# GENERAL register map
Vendor: Texas Instruments
Peripheral module from a debugger description file (folder omap34xx).
Registers are 32-bit, read-only, reset 0x0 unless marked. A register's access mark holds for its fields unless they carry their own. Offsets are as the file gives them; lines under a group give offsets from that group; [hi:lo] are bit positions; {n}, {i} and the like mark numbered series; 'fields as' and 'values as' point back to an identical list; <NAME> marks a mode.

## GENERAL
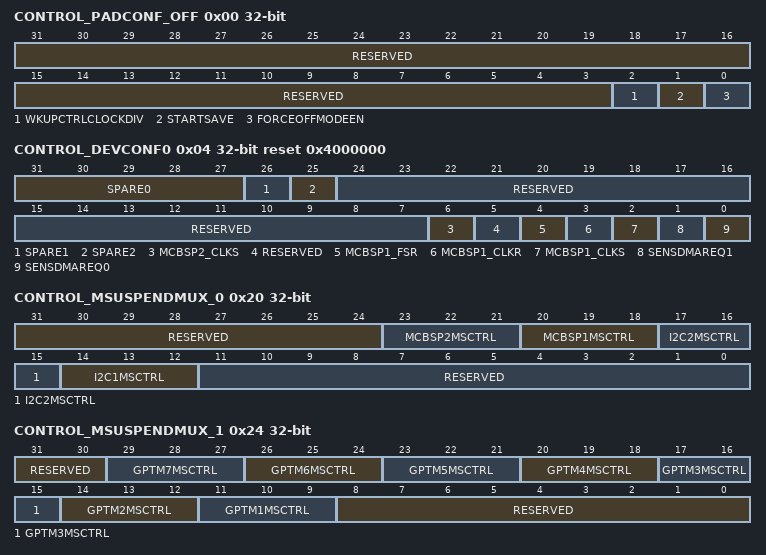
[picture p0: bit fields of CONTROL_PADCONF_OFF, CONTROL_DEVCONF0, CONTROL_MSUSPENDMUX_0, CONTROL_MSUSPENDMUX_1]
0x00 CONTROL_PADCONF_OFF access per field — Off mode pad configuration register
  [31:3] RESERVED ro — Read returns reset value.
  [2] WKUPCTRLCLOCKDIV rw — Wkup_ctrl module clock divider
  [1] STARTSAVE rw — Start pad configuration registers save mechanism
  [0] FORCEOFFMODEEN rw — Force OFF mode active
0x04 CONTROL_DEVCONF0 access per field reset 0x4000000 — Static device configuration register-0. Module dedicated functions
  [31:27] SPARE0 rw — Spare bits
  [26] SPARE1 rw — Spare bit
  [25] SPARE2 rw — Spare bit
  [24:7] RESERVED ro — Read returns reset value
  [6] MCBSP2_CLKS rw — Select the CLKS input for the module McBSP2Note : There are no external pins McBSP2_CLKR and McBSP2_FSR for the module McBSP2. For this module, CLKR input is from the pin McBSP2_CLKX and FSR input is from the pin McBSP2_FSX .
  [5] RESERVED ro — Read returns reset value.
  [4] MCBSP1_FSR rw — Select the FSR input for the module McBSP1
  [3] MCBSP1_CLKR rw — Select the CLKR input for the module McBSP1
  [2] MCBSP1_CLKS rw — Select the CLKS input for the module McBSP1
  [1] SENSDMAREQ1 rw — Set sensitivity on SYS.DMAREQ1 input pin
  [0] SENSDMAREQ0 rw — Set sensitivity on SYS.DMAREQ0 input pin
0x20 CONTROL_MSUSPENDMUX_0 access per field — MSuspend Control register: control the use of MSuspend signals at module level
  [31:24] RESERVED ro — Read returns reset value.
  [23:21] MCBSP2MSCTRL rw — Control McBSP_2 sensitivity to MCU and/or DSP MSuspend signals
  [20:18] MCBSP1MSCTRL rw — Control McBSP_1 sensitivity to MCU and/or DSP MSuspend signals
  [17:15] I2C2MSCTRL rw — Control I2C_2 sensitivity to MCU and/or DSP MSuspend signals
  [14:12] I2C1MSCTRL rw — Control I2C_1 sensitivity to MCU and/or DSP MSuspend signals
  [11:0] RESERVED ro — Read returns reset value.
0x24 CONTROL_MSUSPENDMUX_1 access per field — MSuspend Control register : control the use of MSuspend signals at module level
  [31:30] RESERVED ro — Read returns reset value.
  [3n+8:3n+6] GPTM{n}MSCTRL rw (n=1..7) — Control General Purpose Timer {n} sensitivity to MCU and/or DSP MSuspend signals
  [8:0] RESERVED ro — Read returns reset value.
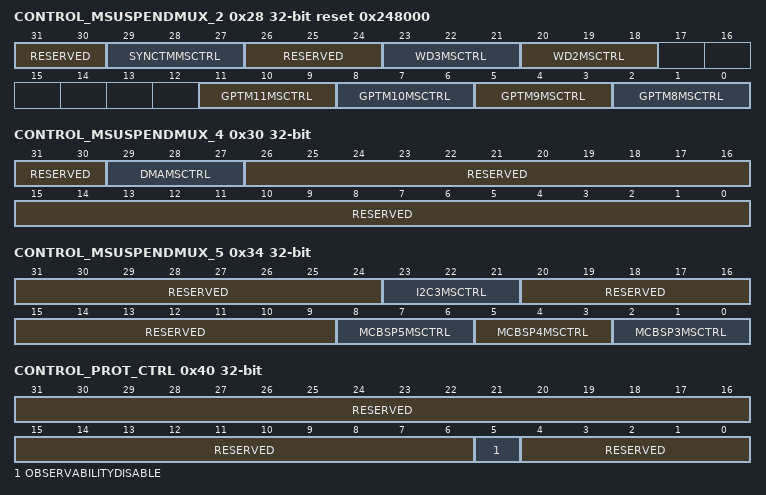
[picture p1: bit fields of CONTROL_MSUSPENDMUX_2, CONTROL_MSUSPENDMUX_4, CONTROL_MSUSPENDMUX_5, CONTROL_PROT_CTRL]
0x28 CONTROL_MSUSPENDMUX_2 access per field reset 0x248000 — MSuspend Control register : control the use of MSuspend signals at module level
  [31:30] RESERVED ro — Read returns reset value.
  [29:27] SYNCTMMSCTRL rw — Control Sync Timer32K sensitivity to MCU and/or DSP MSuspend signals
  [26:24] RESERVED ro — Read returns reset value.
  [23:21] WD3MSCTRL rw — Control Watch Dog 4 sensitivity to MCU and/or DSP MSuspend signals
  [20:18] WD2MSCTRL rw — Control Watch Dog 2 sensitivity to MCU and/or DSP MSuspend signals
  [3n-22:3n-24] GPTM{n}MSCTRL rw (n=8..11) — Control General Purpose Timer {n} sensitivity to MCU and/or DSP MSuspend signals
0x2C CONTROL_MSUSPENDMUX_3 — MSuspend Control register : control the use of MSuspend signals at module level
  [31:0] RESERVED — Read returns reset value.
0x30 CONTROL_MSUSPENDMUX_4 access per field — MSuspend Control register: control the use of MSuspend signals at module level
  [31:30] RESERVED ro — Read returns reset value.
  [29:27] DMAMSCTRL rw — Control DMA sensitivity to MCU and/or DSP MSuspend signals
  [26:0] RESERVED ro — Read returns reset value.
0x34 CONTROL_MSUSPENDMUX_5 access per field — MSuspend Control register: control the use of MSuspend signals at module levelNot used
  [31:24] RESERVED ro — Read returns reset value.
  [23:21] I2C3MSCTRL rw — Control I2C-3 Sensitivity to MCU and/or DSP MSuspend Signals
  [20:9] RESERVED ro — Read returns reset value.
  [8:6] MCBSP5MSCTRL rw — Control McBSP-5 Sensitivity to MCU and/or DSP MSuspend Signals
  [5:3] MCBSP4MSCTRL rw — Control McBSP-4 Sensitivity to MCU and/or DSP MSuspend Signals
  [2:0] MCBSP3MSCTRL rw — Control McBSP-3 Sensitivity to MCU and/or DSP MSuspend Signals
0x40 CONTROL_PROT_CTRL access not given — Control register
  [31:6] RESERVED ro — Read returns reset value
  [5] OBSERVABILITYDISABLE — Control the observability feature (access R/OCO)
  [4:0] RESERVED ro — Read returns reset value.
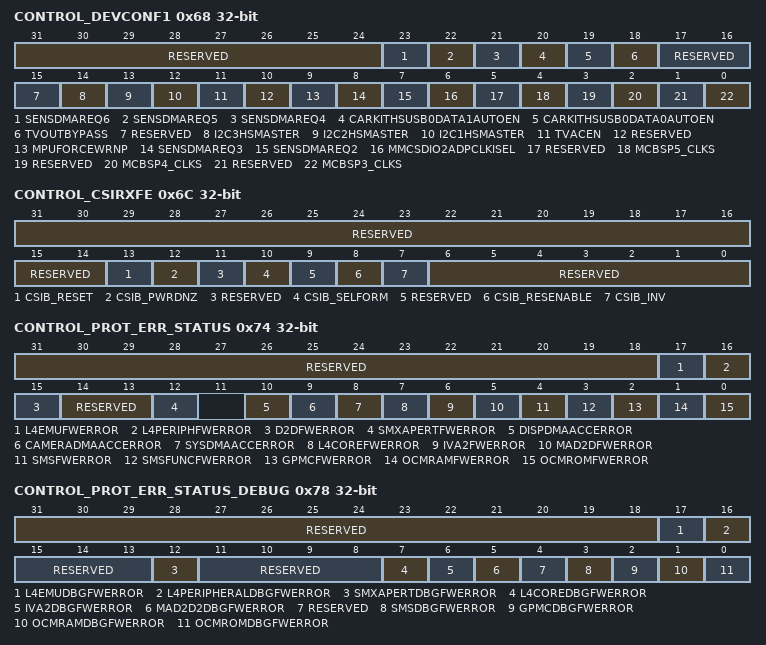
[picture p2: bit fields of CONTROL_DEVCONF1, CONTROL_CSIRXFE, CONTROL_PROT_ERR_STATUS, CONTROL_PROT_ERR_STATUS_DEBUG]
0x68 CONTROL_DEVCONF1 access per field — Static device configuration register-1. Module dedicated functions
  [31:24] RESERVED ro — Read returns reset value
  [23] SENSDMAREQ6 rw — Set sensitivity on SYS.nDMAREQ6 input pin
  [22] SENSDMAREQ5 rw — Set sensitivity on SYS.nDMAREQ5 input pin
  [21] SENSDMAREQ4 rw — Set sensitivity on SYS.nDMAREQ4 input pin
  [20] CARKITHSUSB0DATA1AUTOEN rw — Enable force from HSUB0 DATA1 pad configuration MuxMode when CARKITEN is generated:
  [19] CARKITHSUSB0DATA0AUTOEN rw — Enable force from HSUB0 DATA0 pad configuration MuxMode when CARKITEN is generated
  [18] TVOUTBYPASS rw — Active high enable Dual 10-bit video DAC TV out bypass
  [17:15] RESERVED ro — Read returns reset value.
  [14] I2C3HSMASTER rw — Active-high enable of I2C3 I/O internal pull-up (used for master component)
  [13] I2C2HSMASTER rw — Active-high enable of I2C2 I/O internal pull-up (used for master component)
  [12] I2C1HSMASTER rw — Active-high enable of I2C1 I/O internal pull-up (used for master component)
  [11] TVACEN rw — TV AC coupled load enable for TV output
  [10] RESERVED ro — Read returns reset value.
  [9] MPUFORCEWRNP rw — Force MPU writes to others to be non posted
  [8] SENSDMAREQ3 rw — Set sensitivity on SYS.nDMAREQ3 input pin
  [7] SENSDMAREQ2 rw — Set sensitivity on SYS.nDMAREQ2 input pin
  [6] MMCSDIO2ADPCLKISEL rw — MMC/SDIO2 Module Input Clock selection
  [5] RESERVED ro — Read returns reset value.
  [4] MCBSP5_CLKS rw — Select the CLKS input for the module McBSP5
  [3] RESERVED ro — Read returns reset value.
  [2] MCBSP4_CLKS rw — Select the CLKS input for the module McBSP4
  [1] RESERVED ro — Read returns reset value.
  [0] MCBSP3_CLKS rw — Select the CLKS input for the module McBSP3
0x6C CONTROL_CSIRXFE access per field — This register makes possible to control some settings of CSIRXFE cells used in the design
  [31:14] RESERVED ro — Read returns reset value.
  [13] CSIB_RESET rw — Active Low asynchronous reset signal for CSIb_interface
  [12] CSIB_PWRDNZ rw — Power Down control for CSIb_interface0: CSIb differential transceiver is powered down1: CSIb differential transceiver is active
  [11] RESERVED ro — Read returns reset value.
  [10] CSIB_SELFORM rw — CSI receiver transmission format selection for CSIb_interface0: Data/clock transmission format.1: Data/Strobe transmission format
  [9] RESERVED ro — Read returns reset value.
  [8] CSIB_RESENABLE rw — Enable resistor for CSIb_interface0: CSIb internal resistor is disconnected (use external termination resistor)1: CSIb internal resistor is enabled
  [7] CSIB_INV rw — Strobe/Clock inversion control for CSIb_interface0: CSIb internal data latched on rising edge of clock1: CSIb internal data latched on falling edge of clock
  [6:0] RESERVED rw — Read returns reset value.
0x74 CONTROL_PROT_ERR_STATUS — Protection error status register
  [31:18] RESERVED — Read returns reset value.
  [17] L4EMUFWERROR — L4 Emulation Firewall Error
    0=No L4 Emulation interconnect firewall error; 1=L4 Emulation interconnect firewall error
  [16] L4PERIPHFWERROR — L4 Peripheral Firewall Error
    0=No L4 Peripheral interconnect firewall error; 1=L4 Peripheral interconnect firewall error
  [15] D2DFWERROR — D2D Firewalll error
    0=No D2D firewall error; 1=D2D firewall error
  [14:13] RESERVED — Read returns reset value.
  [12] SMXAPERTFWERROR — L3 Register target Firewall error
    0=No L3 Register Target firewall error; 1=L3 Register Target firewall error
  [10] DISPDMAACCERROR — Disp Dma Access Error
    0=No access error to DISP DMA protection channels; 1=Unauthorized access to a DISP DMA protection channel
  [9] CAMERADMAACCERROR — Camera Dma Access Error
    0=No access error to Camera DMA protection channels; 1=Unauthorized access to a Camera DMA protection channel
  [8] SYSDMAACCERROR — sDma Access Error
    0=No access error to sDMA protection channels; 1=Unauthorized access to a sDMA protection channel
  [7] L4COREFWERROR — L4 Protection Firewall Error
    0=No error from L4 Core protection firewall; 1=Error from L4 Core protection firewall
  [6] IVA2FWERROR — IVA2 Protection Firewall Error
    0=No error from IVA2 protection firewall; 1=Error from IVA2 protection firewall
  [5] MAD2DFWERROR — MAD2D Firewall Error
    0=No MAD2D functional firewall error; 0=No MAD2D functional firewall error
  [4] SMSFWERROR — SMS Firewall Error
    0=No SMS firewall error; 1=SMS firewall error
  [3] SMSFUNCFWERROR — SMS Functional Firewall Error
    0=No SMS functional firewall error; 1=SMS functional firewall error
  [2] GPMCFWERROR — GPMC Firewall Error
    0=No error from GPMC protection firewall; 1=Error from GPMC protection firewall
  [1] OCMRAMFWERROR — On Chip Ram Firewall Error
    0=No error from On Chip RAM protection firewall; 1=Error from On Chip RAM protectionfirewall
  [0] OCMROMFWERROR — On Chip Rom Firewall Error
    0=No error from On Chip ROM protection firewall; 1=Error from On Chip ROM protection firewall
0x78 CONTROL_PROT_ERR_STATUS_DEBUG — Protection Error Status Debug Register
  [31:18] RESERVED — Read returns reset value
  [17] L4EMUDBGFWERROR — L4 Emulation Debug Firewall Error
  [16] L4PERIPHERALDBGFWERROR — L4 Peripheral Debug Firewall Error
  [15:13] RESERVED — Read returns reset value
  [12] SMXAPERTDBGFWERROR — L3 Register target Debug Firewall error
  [11:8] RESERVED — Read returns reset value.
  [7] L4COREDBGFWERROR — L4 Core Debug Firewall Error
  [6] IVA2DBGFWERROR — IVA2 Debug Firewall Error
  [5] MAD2D2DBGFWERROR — MAD2D Debug Firewall Error
  [4] RESERVED — Read returns reset value.
  [3] SMSDBGFWERROR — SMS Debug Firewall Error
  [2] GPMCDBGFWERROR — GPMC Debug Firewall Error
  [1] OCMRAMDBGFWERROR — On Chip Ram Debug Firewall Error
  [0] OCMROMDBGFWERROR — On Chip Rom Debug Firewall Error
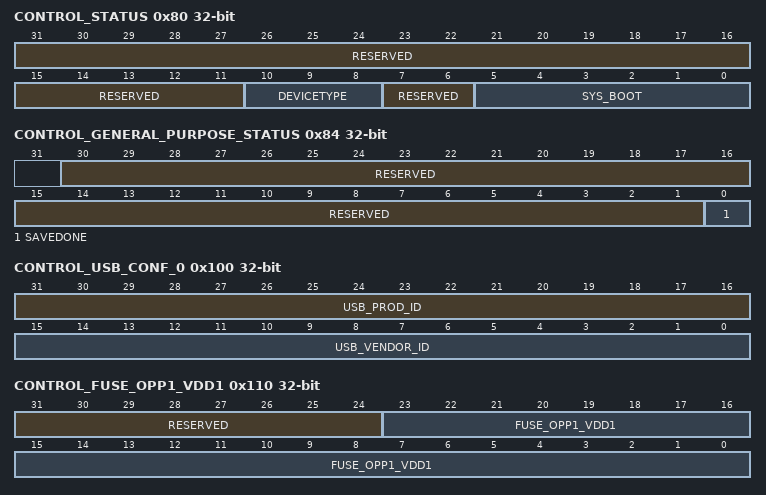
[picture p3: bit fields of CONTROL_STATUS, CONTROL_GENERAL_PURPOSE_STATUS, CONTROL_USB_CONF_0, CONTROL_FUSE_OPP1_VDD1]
0x80 CONTROL_STATUS reset not defined — Control Module Status register: latches system information at reset time
  [31:11] RESERVED — Read returns reset value.
  [10:8] DEVICETYPE — Device type captured at reset timeOther values: Reserved .
    3=GP device
  [7:6] RESERVED — Read returns reset value.
  [5:0] SYS_BOOT — sys_boot[5:0] pin values sampled at power-on reset
0x84 CONTROL_GENERAL_PURPOSE_STATUS — Status bits reflecting chip internal states
  [30:1] RESERVED — Read returns reset value.
  [0] SAVEDONE — Pad configuration save status
{0x90+4i} CONTROL_RPUB_KEY_H_{i} (i=0..4) — Root_public_key_hash; B-field
  [31:0] RPKH_{i} — Root_public_key_hash {i}
0x100 CONTROL_USB_CONF_0 — USB Fuse conf [31:0],USB Product ID [31:16] Vendor ID [15:0]
  [31:16] USB_PROD_ID — USB Product ID [31:16]
  [15:0] USB_VENDOR_ID — Vendor ID [15:0]
0x104 CONTROL_USB_CONF_1 — USB Fuse conf 1, SEQ_DISADAPTCLK[1], USB PHY detection mode [0]
  [31:0] USB_CONF_1 — USB Fuse conf 1
0x110 CONTROL_FUSE_OPP1_VDD1 (reset mask 0xFF000000) — Standard Fuse OPP1 VDD1 [23:0]
  [31:24] RESERVED — Read returns reset value.
  [23:0] FUSE_OPP1_VDD1 — value for OPP1 VDD1
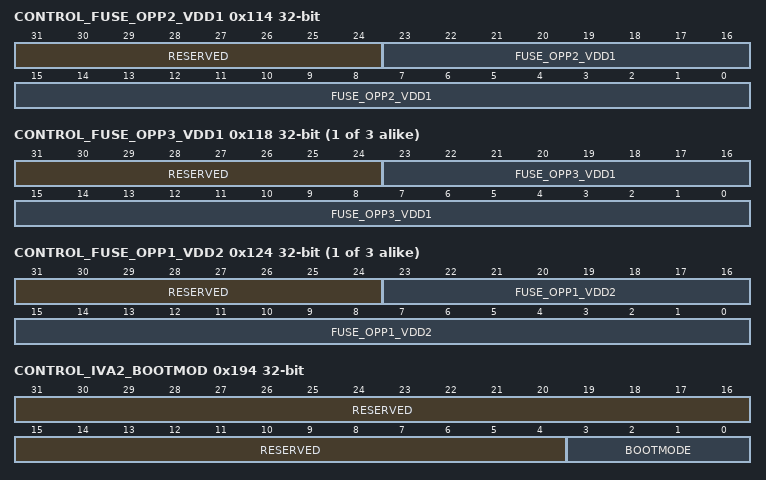
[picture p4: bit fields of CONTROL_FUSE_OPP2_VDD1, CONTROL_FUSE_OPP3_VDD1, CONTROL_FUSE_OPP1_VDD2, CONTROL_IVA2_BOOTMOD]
0x114 CONTROL_FUSE_OPP2_VDD1 (reset mask 0xFF000000) — Standard Fuse OPP2 VDD1 [23:0]
  [31:24] RESERVED — Read returns reset value.
  [23:0] FUSE_OPP2_VDD1 — value for OPP2_VDD1
{0x10C+4i} CONTROL_FUSE_OPP{i}_VDD1 (reset mask 0xFF000000) (i=3..5) — Standard Fuse OPP{i} VDD1 [23:0]
  [31:24] RESERVED — Read returns reset value.
  [23:0] FUSE_OPP{i}_VDD1 — value for OPP{i} VDD1
{0x120+4i} CONTROL_FUSE_OPP{i}_VDD2 (reset mask 0xFF000000) (i=1..3) — Standard Fuse OPP{i} VDD2 [23:0]
  [31:24] RESERVED — Read returns reset value.
  [23:0] FUSE_OPP{i}_VDD2 — value for OPP{i} VDD2
0x190 CONTROL_IVA2_BOOTADDR access per field — This register defines the physical address of the IVA2 boot loader
  [31:10] BOOTLOADADDR rw — Physical Address of the IVA2 boot loader. This is an index to a 4kByte page
0x194 CONTROL_IVA2_BOOTMOD access per field — This register defines the IVA2 bootmode
  [31:4] RESERVED ro — Read returns reset value.
  [3:0] BOOTMODE rw — Boot mode of the IVA2
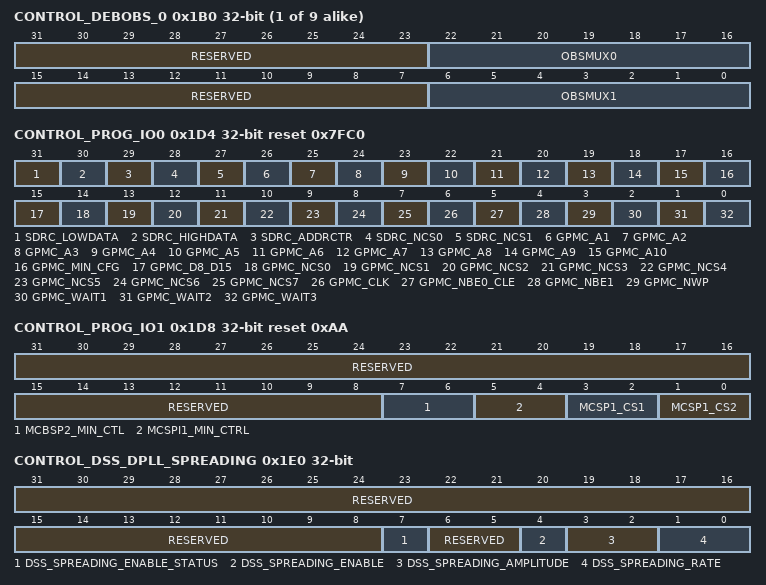
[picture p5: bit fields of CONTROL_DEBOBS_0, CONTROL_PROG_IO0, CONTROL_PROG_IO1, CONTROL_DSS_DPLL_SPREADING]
{0x1B0+4i} CONTROL_DEBOBS_{i} access per field (i=0..8) — Select the set of signals to be observed for hw_dbg{2i}, hw_dbg{2i+1}
  [31:23] RESERVED ro — Read returns reset value.
  [22:16] OBSMUX{2i} rw — Select the set of signals to be exported for WKUPOBSMUX{2i}
  [15:7] RESERVED ro — Read returns reset value.
  [6:0] OBSMUX{2i+1} rw — Select the set of signals to be exported for WKUPOBSMUX{2i+1}
0x1D4 CONTROL_PROG_IO0 rw reset 0x7FC0 — Configure drive strength of I/O cells
  [31] SDRC_LOWDATA — Drive strength for output load:0x0: Drive strength set to low 2-6 pF 0x1: Drive strength set to high 6-12 pF
  [30] SDRC_HIGHDATA — Drive strength for output load:0x0: Drive strength set to low 2-6 pF 0x1: Drive strength set to high 6-12 pF
  [29] SDRC_ADDRCTR — Drive strength for output load:0x0: Drive strength set to low 2-6 pF 0x1: Drive strength set to high 6-12 pF
  [28] SDRC_NCS0 — Drive strength for output load:0x0: Drive strength set to low 2-6 pF 0x1: Drive strength set to high 6-12 pF
  [27] SDRC_NCS1 — Drive strength for output load:0x0: Drive strength set to low 2-6 pF 0x1: Drive strength set to high 6-12 pF
  [27-n] GPMC_A{n} (n=1..10) — Drive strength for output load:0x0: Drive strength set to low 2-6 pF 0x1: Drive strength set to high 6-12 pF
  [16] GPMC_MIN_CFG — Drive strength for output load:0x0: Drive strength set to low 2-6 pF 0x1: Drive strength set to high 6-12 pF
  [15] GPMC_D8_D15 — Drive strength for output load:0x0: Drive strength set to low 2-6 pF 0x1: Drive strength set to high 6-12 pF
  [14-n] GPMC_NCS{n} (n=0..7) — Drive strength for output load:0x0: Drive strength set to low 2-6 pF 0x1: Drive strength set to high 6-12 pF
  [6] GPMC_CLK — Drive strength for output load:0x0: Drive strength set to low 2-6 pF 0x1: Drive strength set to high 6-12 pF
  [5] GPMC_NBE0_CLE — Drive strength for output load:0x0: Drive strength set to low 2-6 pF 0x1: Drive strength set to high 6-12 pF
  [4] GPMC_NBE1 — Drive strength for output load:0x0: Drive strength set to low 2-6 pF 0x1: Drive strength set to high 6-12 pF
  [3] GPMC_NWP — Drive strength for output load:0x0: Drive strength set to low 2-6 pF 0x1: Drive strength set to high 6-12 pF
  [2] GPMC_WAIT1 — Drive strength for output load:0x0: Drive strength set to low 2-6 pF 0x1: Drive strength set to high 6-12 pF
  [1] GPMC_WAIT2 — Drive strength for output load:0x0: Drive strength set to low 2-6 pF 0x1: Drive strength set to high 6-12 pF
  [0] GPMC_WAIT3 — Drive strength for output load:0x0: Drive strength set to low 2-6 pF 0x1: Drive strength set to high 6-12 pF
0x1D8 CONTROL_PROG_IO1 access per field reset 0xAA — Configure drive strength of I/O cells
  [31:8] RESERVED ro — Read returns reset value
  [7:6] MCBSP2_MIN_CTL rw — Drive strength for impedance and current output:0x0: Drive strength set to 20 Ω, 8 mA 0x2: Drive strength set to 25 Ω, 6 mA 0x1: Drive strength set to 40 Ω, 4 mA 0x3: Drive strength set to 65 Ω, 2 mA
  [5:4] MCSPI1_MIN_CTRL rw — Drive strength for impedance and current output:0x0: Drive strength set to 20 Ω, 8 mA 0x2: Drive strength set to 25 Ω, 6 mA 0x1: Drive strength set to 40 Ω, 4 mA 0x3: Drive strength set to 65 Ω, 2 mA
  [3:2] MCSP1_CS1 rw — Drive strength for impedance and current output:0x0: Drive strength set to 20 Ω, 8 mA 0x2: Drive strength set to 25 Ω, 6 mA 0x1: Drive strength set to 40 Ω, 4 mA 0x3: Drive strength set to 65 Ω, 2 mA
  [1:0] MCSP1_CS2 rw — Drive strength for impedance and current output:0x0: Drive strength set to 20 Ω, 8 mA 0x2: Drive strength set to 25 Ω, 6 mA 0x1: Drive strength set to 40 Ω, 4 mA 0x3: Drive strength set to 65 Ω, 2 mA
0x1E0 CONTROL_DSS_DPLL_SPREADING access per field (reset mask 0xFFFFFF7F) — This register controls the EMI Reduction feature for Display_SS/DSI DPLL
  [31:8] RESERVED ro — Reads return zero
  [7] DSS_SPREADING_ENABLE_STATUS ro — Indicates the status of the SSC feature
  [6:5] RESERVED ro — Reads return zero
  [4] DSS_SPREADING_ENABLE rw — Enables/disables EMI Reduction feature (Spreading):
    0=Modulation stops at the end of the current modulation cycle; 1=Modulation cycle is started
  [3:2] DSS_SPREADING_AMPLITUDE rw — Controls the modulation index.This index (K) is a ratio of Frequency spread (Δf) and spreading rate (f) .
  [1:0] DSS_SPREADING_RATE rw — Controls the rate of frequency modulation:
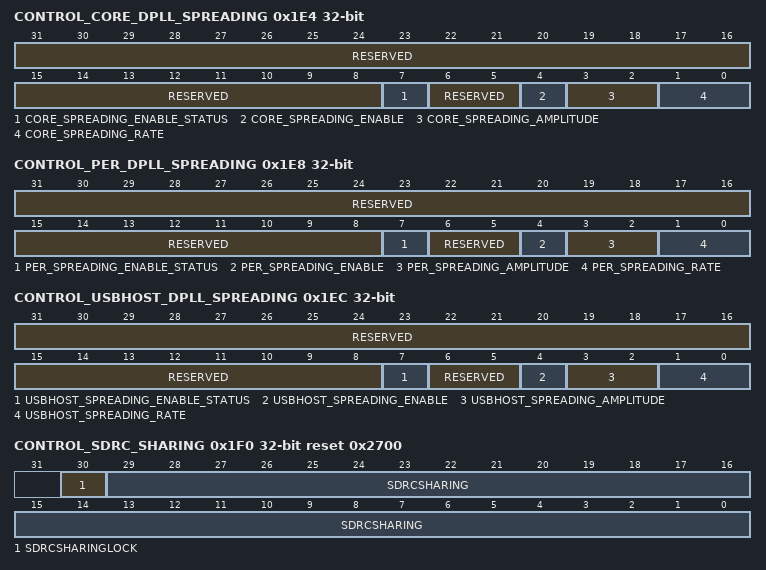
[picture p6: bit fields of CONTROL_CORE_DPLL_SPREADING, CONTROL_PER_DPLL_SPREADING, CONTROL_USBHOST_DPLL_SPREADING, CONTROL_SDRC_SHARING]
0x1E4 CONTROL_CORE_DPLL_SPREADING access per field (reset mask 0xFFFFFF7F) — This register controls the EMI Reduction feature for CORE domain DPLL
  [31:8] RESERVED ro — Reads return zero
  [7] CORE_SPREADING_ENABLE_STATUS ro — Indicates the status of the SSC feature
  [6:5] RESERVED ro — Reads return zero
  [4] CORE_SPREADING_ENABLE rw — Enables/disables EMI Reduction feature (Spreading):
    values as CONTROL_DSS_DPLL_SPREADING.DSS_SPREADING_ENABLE
  [3:2] CORE_SPREADING_AMPLITUDE rw — Controls the modulation index.This index (K) is a ratio of Frequency spread (Δf) and spreading rate (f) .
  [1:0] CORE_SPREADING_RATE rw — Controls the rate of frequency modulation:
0x1E8 CONTROL_PER_DPLL_SPREADING access per field (reset mask 0xFFFFFF7F) — This register controls the EMI Reduction feature for PER domain DPLL
  [31:8] RESERVED ro — Reads return 0
  [7] PER_SPREADING_ENABLE_STATUS ro — Indicates the status of the Spreading feature
  [6:5] RESERVED ro — Reads return 0
  [4] PER_SPREADING_ENABLE rw — Enables/disables EMI Reduction feature (Spreading):
    values as CONTROL_DSS_DPLL_SPREADING.DSS_SPREADING_ENABLE
  [3:2] PER_SPREADING_AMPLITUDE rw — Controls the modulation index.This index (K) is a ratio of the spreading frequency (Δf) and spreading rate (f) .
  [1:0] PER_SPREADING_RATE rw — Controls the rate of frequency modulation:
0x1EC CONTROL_USBHOST_DPLL_SPREADING access per field (reset mask 0xFFFFFF7F) — This register controls the EMI Reduction feature for USBHOST DPLL
  [31:8] RESERVED ro — Reads return zero
  [7] USBHOST_SPREADING_ENABLE_STATUS ro — Indicates the status of the Spreading feature
  [6:5] RESERVED ro — Reads return zero
  [4] USBHOST_SPREADING_ENABLE rw — Enables/disables EMI Reduction feature (Spreading):
    values as CONTROL_DSS_DPLL_SPREADING.DSS_SPREADING_ENABLE
  [3:2] USBHOST_SPREADING_AMPLITUDE rw — Controls the modulation index.This index (K) is a ratio of Frequency spread (Δf) and spreading rate (f) .
  [1:0] USBHOST_SPREADING_RATE rw — Controls the rate of frequency modulation:
0x1F0 CONTROL_SDRC_SHARING access not given reset 0x2700 — SDRC Sharing configuration register
  [30] SDRCSHARINGLOCK rw — Exported value to SDRC.SDRC_SHARING[30]For more information, see ,
  [29:0] SDRCSHARING rw — Exported value to SDRC.SDRC_SHARING[29:0]For more information, see ,
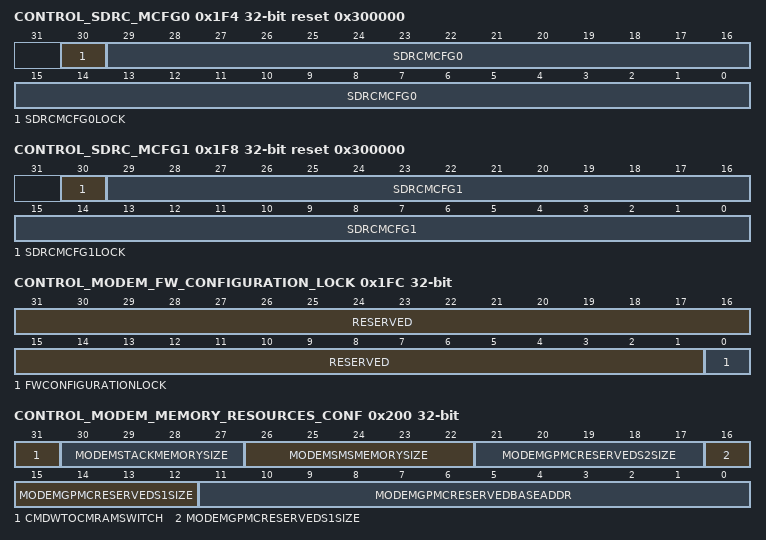
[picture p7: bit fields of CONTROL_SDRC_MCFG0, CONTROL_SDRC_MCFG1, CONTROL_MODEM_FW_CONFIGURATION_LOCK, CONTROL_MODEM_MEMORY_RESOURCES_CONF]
0x1F4 CONTROL_SDRC_MCFG0 access not given reset 0x300000 — SDRC MCFG Configuration register-0
  [30] SDRCMCFG0LOCK rw — Exported value to SDRC.SDRC_MCFG_0[30]For more information, see ,
  [29:0] SDRCMCFG0 rw — Exported value to SDRC.SDRC_MCFG_0[29:0]For more information, see ,
0x1F8 CONTROL_SDRC_MCFG1 access not given reset 0x300000 — SDRC MCFG Configuration register-1
  [30] SDRCMCFG1LOCK rw — Exported value to SDRC.SDRC_MCFG_1[30]For more information, see ,
  [29:0] SDRCMCFG1 rw — Exported value to SDRC.SDRC_MCFG_1[29:0]For more information, see ,
0x1FC CONTROL_MODEM_FW_CONFIGURATION_LOCK access not given — Allows locking of the modem isolation registers in the SCM until the next battery removal.
  [31:1] RESERVED ro — Read returns reset value.
  [0] FWCONFIGURATIONLOCK — Allows locking of the modem isolation registers in the SCM until the next battery removal. (access Refer to)
0x200 CONTROL_MODEM_MEMORY_RESOURCES_CONF access not given — Modem Memory Resources Conf
  [31] CMDWTOCMRAMSWITCH — Select if CMDWT or OCMRAM is accessible by the Modem (access Refer to)
  [30:27] MODEMSTACKMEMORYSIZE — Configuration of the modem stack memory size (access Refer to)
  [26:22] MODEMSMSMEMORYSIZE — Configuration of the SMS modem memory (access Refer to)
  [21:17] MODEMGPMCRESERVEDS2SIZE — Configuration of the GPMC modem shared section size (access Refer to)
  [16:12] MODEMGPMCRESERVEDS1SIZE — Configuration of the GPMC modem reserved section size (access Refer to)
  [11:0] MODEMGPMCRESERVEDBASEADDR — Configuration of the GPMC base address of the modem reserved section. This base address is configurable in 1Mbyte step. (access Refer to)
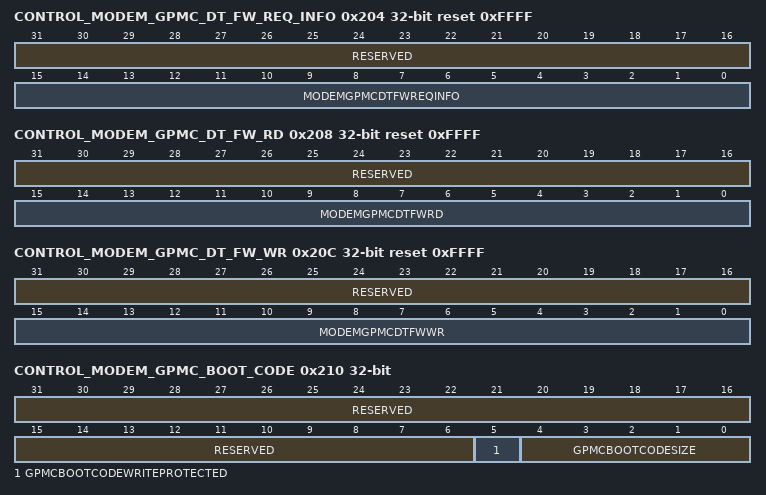
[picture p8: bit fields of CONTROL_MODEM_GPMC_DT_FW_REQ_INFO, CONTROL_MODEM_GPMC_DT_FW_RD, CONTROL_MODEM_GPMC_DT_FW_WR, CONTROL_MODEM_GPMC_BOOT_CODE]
0x204 CONTROL_MODEM_GPMC_DT_FW_REQ_INFO access not given reset 0xFFFF — Modem GPMC Default firewall request info register
  [31:16] RESERVED ro — Read returns reset value.
  [15:0] MODEMGPMCDTFWREQINFO — Exported values to the GPMC firewall region1 REQ_INFO_PERMISSION field (access Refer to)
0x208 CONTROL_MODEM_GPMC_DT_FW_RD access not given reset 0xFFFF — Modem GPMC Default firewall read permission register
  [31:16] RESERVED ro — Read returns reset value.
  [15:0] MODEMGPMCDTFWRD — Exported values to the GPMC firewall region1 READ_PERMISSION field (access Refer to)
0x20C CONTROL_MODEM_GPMC_DT_FW_WR access not given reset 0xFFFF — Modem GPMC Default firewall write permission register
  [31:16] RESERVED ro — Read returns reset value.
  [15:0] MODEMGPMCDTFWWR — Exported values to the GPMC firewall region1 WRITE_PERMISSION field (access Refer to)
0x210 CONTROL_MODEM_GPMC_BOOT_CODE access not given — GPMC Flash Boot Code protection register
  [31:6] RESERVED ro — Read returns reset value.
  [5] GPMCBOOTCODEWRITEPROTECTED — When set HIGH the Flash boot code area is write protected. (access See)
  [4:0] GPMCBOOTCODESIZE — Size of the Flash boot code to protect (access See)
0x214 CONTROL_MODEM_SMS_RG_ATT1 access not given reset 0xFFFFFFFF — Modem SMS Default firewall register
  [31:0] SMSRGATT1 — Exported values to the SMS firewall region1 SMS_RG_ATT1 field (access Refer to)
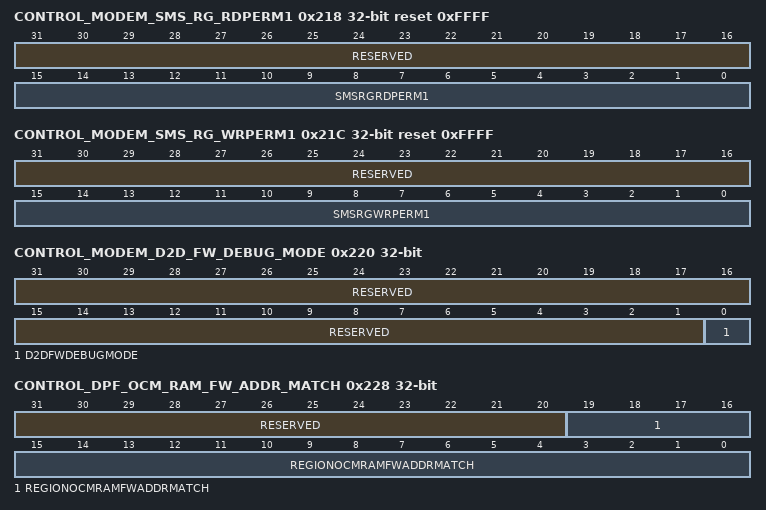
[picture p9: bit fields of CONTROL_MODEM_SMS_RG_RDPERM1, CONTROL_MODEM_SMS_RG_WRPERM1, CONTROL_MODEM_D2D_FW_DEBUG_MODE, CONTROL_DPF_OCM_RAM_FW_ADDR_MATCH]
0x218 CONTROL_MODEM_SMS_RG_RDPERM1 access not given reset 0xFFFF — Modem SMS Default firewall read permission register
  [31:16] RESERVED ro — Read returns reset value.
  [15:0] SMSRGRDPERM1 — Exported values to the SMS firewall region1 SMS_RG_RDPERM1 field (access Refer to)
0x21C CONTROL_MODEM_SMS_RG_WRPERM1 access not given reset 0xFFFF — Modem SMS Default firewall write permission register
  [31:16] RESERVED ro — Read returns reset value.
  [15:0] SMSRGWRPERM1 — Exported values to the SMS firewall region1 SMS_RG_WRPERM1 field (access Refer to)
0x220 CONTROL_MODEM_D2D_FW_DEBUG_MODE access not given — D2D firewall debug mode register
  [31:1] RESERVED ro — Read returns reset value.
  [0] D2DFWDEBUGMODE — When set to high the L3-D2D FW is in debug mode. (access Refer to)
0x228 CONTROL_DPF_OCM_RAM_FW_ADDR_MATCH — OCM RAM Dynamic Power Framework Handing
  [31:20] RESERVED — Read returns reset value
  [19:0] REGIONOCMRAMFWADDRMATCH — Refer to L3 FW addr_match field
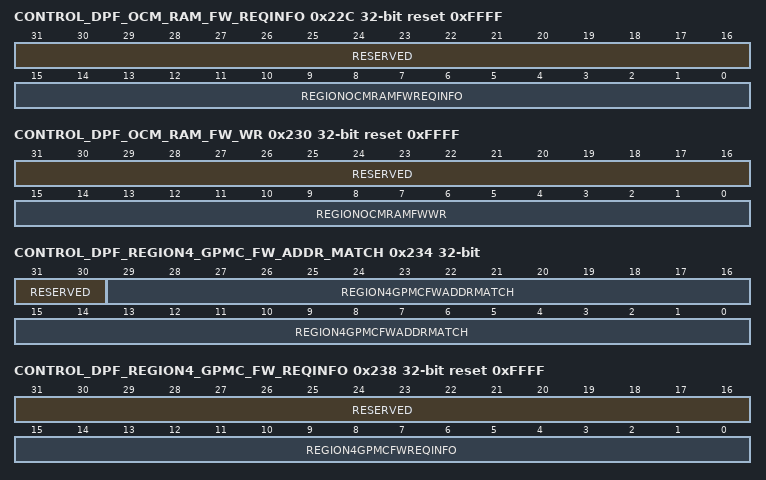
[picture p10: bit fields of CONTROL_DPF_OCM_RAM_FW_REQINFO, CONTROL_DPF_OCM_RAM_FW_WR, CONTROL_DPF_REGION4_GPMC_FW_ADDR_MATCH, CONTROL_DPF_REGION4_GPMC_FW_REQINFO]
0x22C CONTROL_DPF_OCM_RAM_FW_REQINFO reset 0xFFFF — OCM RAM Dynamic Power Framework Handing
  [31:16] RESERVED — Read returns reset value
  [15:0] REGIONOCMRAMFWREQINFO — Refer to L3 FW REQINFO permission field
0x230 CONTROL_DPF_OCM_RAM_FW_WR reset 0xFFFF — OCM RAM Dynamic Power Framework Handing
  [31:16] RESERVED — Read returns reset value
  [15:0] REGIONOCMRAMFWWR — Refer to L3 FW WR permission field
0x234 CONTROL_DPF_REGION4_GPMC_FW_ADDR_MATCH — GPMC Dynamic Power Framework Handing
  [31:30] RESERVED — Read returns reset value
  [29:0] REGION4GPMCFWADDRMATCH — Exported value to L3 FW region 4 GPMC ADDR_MATCH4 field
0x238 CONTROL_DPF_REGION4_GPMC_FW_REQINFO reset 0xFFFF — GPMC Dynamic Power Framework Handing
  [31:16] RESERVED — Read returns reset value.
  [15:0] REGION4GPMCFWREQINFO — Exported value to L3 FW region 4 GPMC REQINFO_PERMISSION_4 field
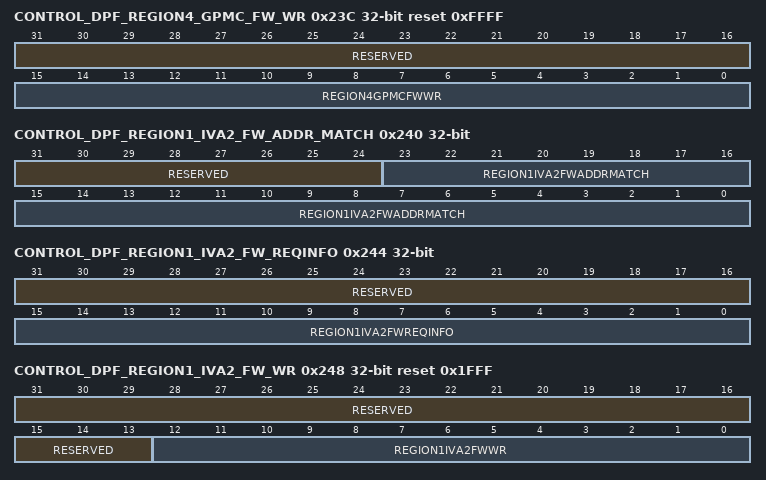
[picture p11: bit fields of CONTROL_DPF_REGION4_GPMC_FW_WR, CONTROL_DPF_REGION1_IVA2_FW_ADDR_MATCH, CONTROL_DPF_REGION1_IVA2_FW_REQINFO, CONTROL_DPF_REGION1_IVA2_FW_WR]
0x23C CONTROL_DPF_REGION4_GPMC_FW_WR reset 0xFFFF — GPMC Dynamic Power Framework Handing
  [31:16] RESERVED — Read returns reset value.
  [15:0] REGION4GPMCFWWR — Exported value to L3 FW region 4 GPMC WRITE_PERMISSION_4 field
0x240 CONTROL_DPF_REGION1_IVA2_FW_ADDR_MATCH — IVA2 Dynamic Power Framework Handing
  [31:24] RESERVED — Read returns reset value
  [23:0] REGION1IVA2FWADDRMATCH — Exported value to L3 FW region 1 IVA2 ADDR_MATCH1 field
0x244 CONTROL_DPF_REGION1_IVA2_FW_REQINFO (reset mask 0xFFFF0000) — IVA2 Dynamic Power Framework Handing
  [31:16] RESERVED — Read returns reset value.
  [15:0] REGION1IVA2FWREQINFO — Exported value to L3 FW region 1 IVA2 REQINFO_PERMISSION_1 field
0x248 CONTROL_DPF_REGION1_IVA2_FW_WR reset 0x1FFF — IVA2 Dynamic Power Framework Handing
  [31:13] RESERVED — Read returns reset value.
  [12:0] REGION1IVA2FWWR — Exported value to L3 FW region 1 IVA2 WRITE_PERMISSION_1 field
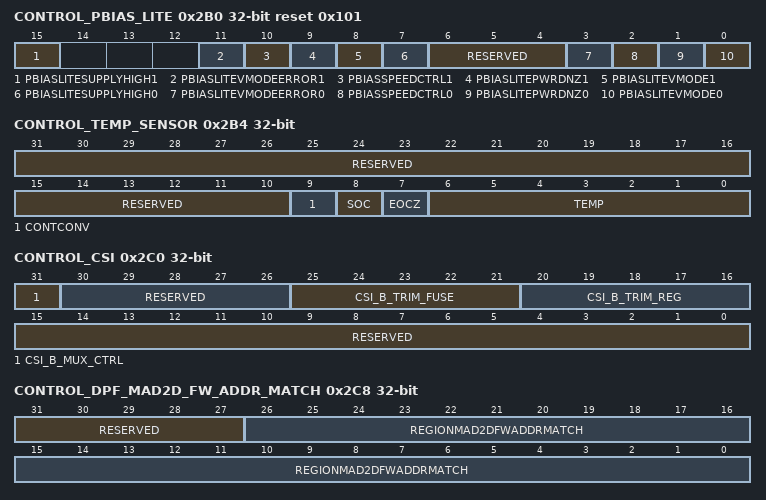
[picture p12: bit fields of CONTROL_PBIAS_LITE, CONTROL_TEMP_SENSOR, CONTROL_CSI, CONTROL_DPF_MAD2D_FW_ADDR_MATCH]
0x2B0 CONTROL_PBIAS_LITE access per field reset 0x101 — This register controls the settings for PBIAS LITE MMC/SD/SDIO1 pins
  [15] PBIASLITESUPPLYHIGH1 ro — Status indicating whether PBIAS1 is supplied by 1.8 V or 3.0 V SIM_VDDS
    1=SIM_VDDS = 3.0 V; 0=SIM_VDDS = 1.8 V
  [11] PBIASLITEVMODEERROR1 ro — Status indicating if the software programmed VMODE level matches the SUPPLY_HI output signal0b0 => VMODE Level same or VMODE level not considered . 0b1 => Indicates VMODE_LEVEL not same as SUPPLY_HI_OUT .
  [10] PBIASSPEEDCTRL1 rw — Speed control for PBIAS1 associated I/O cell0b0 => 26 MHz I/O max speed . 0b1 => 52 MHz I/O max speed .
  [9] PBIASLITEPWRDNZ1 rw — Input signal referenced to VDD2. Software must keep this signal low when SIM_VDDS is ramping up.0b0 => SIM_VDDS ramping up . 0b1 => SIM_VDDS stable .
  [8] PBIASLITEVMODE1 rw — SIM_VDDS voltage level information control from software0b0 => SIM_VDDS = 1.8 V . 0b1 => SIM_VDDS = 3.0 V .
  [7] PBIASLITESUPPLYHIGH0 ro — Status indicating if PBIAS0 is supplied by 1.8 V or 3.0 V MMC1_VDDS0b0 => PBIAS0 is supplied by MMC1_VDDS = 1.8 V . 0b1 => PBIAS0 is supplied by MMC1_VDDS = 3.0 V .
  [6:4] RESERVED ro — Read returns reset value.
  [3] PBIASLITEVMODEERROR0 ro — Status indicating if the software programmed VMODE level matches the SUPPLY_HI output signal0b0 => VMODE Level same or VMODE level not considered . 0b1 => Indicates VMODE_LEVEL not same as SUPPLY_HI_OUT .
  [2] PBIASSPEEDCTRL0 rw — Speed control for MMC I/O0b0 => 26 MHz I/O max speed . 0b1 => 52 MHz I/O max speed .
  [1] PBIASLITEPWRDNZ0 rw — Input signal referenced to VDD2. Software must keep this signal low when MMC1_VDDS is ramping up.0b0 => MMC1_VDDS ramping up . 0b1 => MMC1_VDDS stable .
  [0] PBIASLITEVMODE0 rw — MMC1_VDDS voltage level information control from software0b0 => MMC1_VDDS = 1.8 V . 0b1 => MMC1_VDDS = 3.0 V .
0x2B4 CONTROL_TEMP_SENSOR access per field — temperature sensor register
  [31:10] RESERVED ro — Read returns reset value.
  [9] CONTCONV rw — VDD level digital inputs. When high the ADC is in continuous conversion mode0 : ADC Single Conversion Mode;1 : ADC Continuous Conversion Mode
  [8] SOC rw — ADC Start of Conversion. A transition to high starts a new ADC conversion cycle
  [7] EOCZ ro — ADC End of Conversion. Active low, when CTRL_ TEMP[6:0] is valid
  [6:0] TEMP ro — Temperature data from the ADC. Valid if EOCZ is low
0x2C0 CONTROL_CSI access per field (reset mask 0x801F0000) — Controls CSIb reciever trimming setting
  [31] CSI_B_MUX_CTRL rw — Override CSIb reciever trimming Fuse setting
  [30:26] RESERVED ro — Read returns reset value.
  [25:21] CSI_B_TRIM_FUSE ro — CSIb reciever trimming Fuse value
  [20:16] CSI_B_TRIM_REG rw — CSIb reciever trimming Register control
  [15:0] RESERVED ro — Read returns reset value.
0x2C8 CONTROL_DPF_MAD2D_FW_ADDR_MATCH — MAD2D Dynamic Power Framework Handing
  [31:27] RESERVED — Read returns reset value
  [26:0] REGIONMAD2DFWADDRMATCH — Refer to L3 FW addr match field
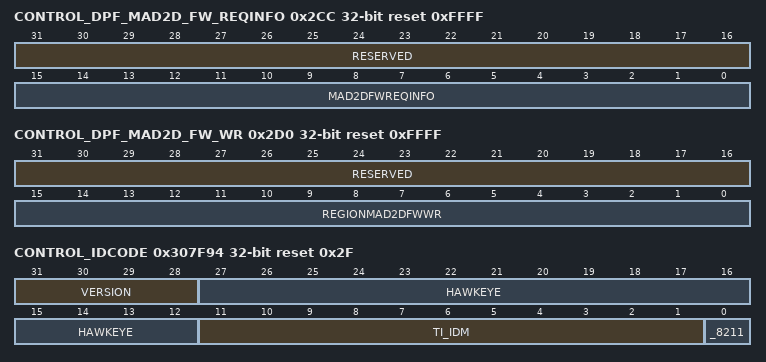
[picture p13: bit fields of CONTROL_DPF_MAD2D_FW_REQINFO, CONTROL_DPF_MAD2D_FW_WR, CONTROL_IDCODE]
0x2CC CONTROL_DPF_MAD2D_FW_REQINFO reset 0xFFFF — MAD2D Dynamic Power Framework Handing
  [31:16] RESERVED — Read returns reset value
  [15:0] MAD2DFWREQINFO — Refer to L3 FW REQINFO permission field
0x2D0 CONTROL_DPF_MAD2D_FW_WR reset 0xFFFF — MAD2D Dynamic Power Framework Handing
  [31:16] RESERVED — Read returns reset value
  [15:0] REGIONMAD2DFWWR — Refer to L3 FW WR permission field
0x307F94 CONTROL_IDCODE reset 0x2F (reset mask 0xFFF) — Device IDCODE
  [31:28] VERSION — Revision number
  [27:12] HAWKEYE — Hawkeye number
  [11:1] TI_IDM — Manufacturer identity (TI)
  [0] _8211 — –
